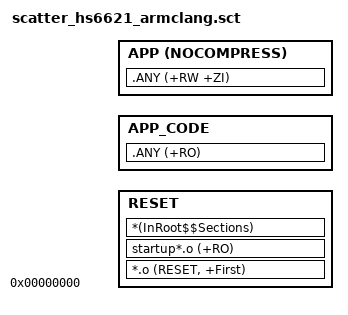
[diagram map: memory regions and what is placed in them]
#! armclang -E --target=arm-arm-none-eabi -mcpu=cortex-m7 -xc
; ***************************************************************
; *** Scatter-Loading Description File generated by Huntersun ***
; ***************************************************************

RAM_LOAD 0x00000000 0x00040000
{
    RESET 0x00000000
    {
        *.o (RESET, +First)
        startup*.o (+RO)
        *(InRoot$$Sections)
    }

    APP_CODE +0
    {
        .ANY (+RO)
    }

    APP 0x20000000 + AlignExpr(ImageLimit(APP_CODE), 16) NOCOMPRESS
    {
        .ANY (+RW +ZI)
    }
}

ScatterAssert(ImageLimit(RESET) < 0x00002000)
ScatterAssert(ImageLimit(APP)   < 0x2000f440)

